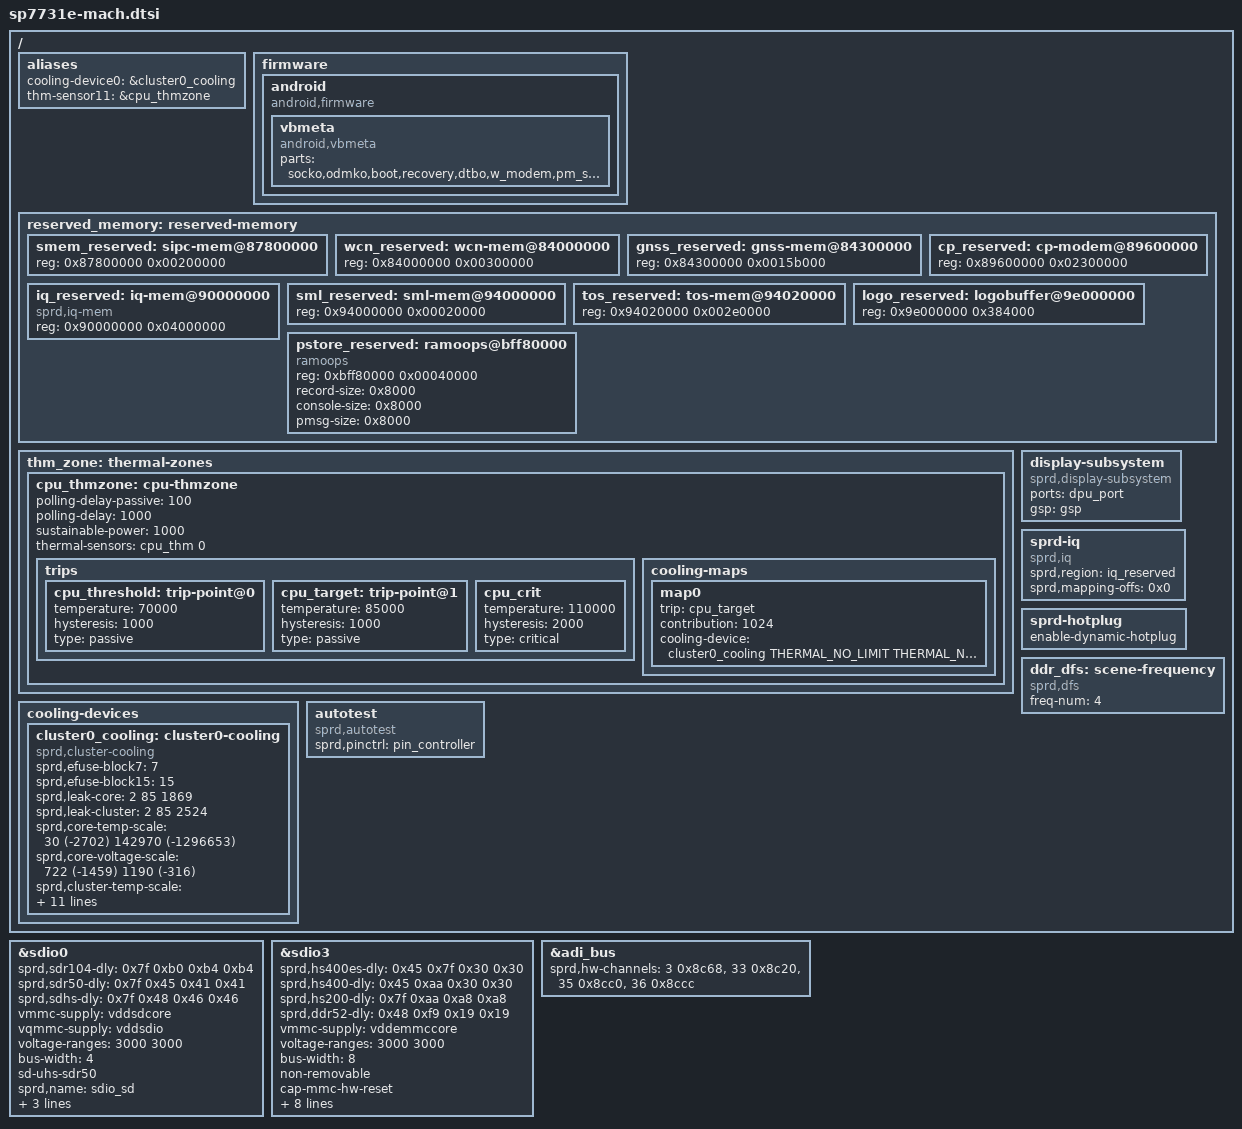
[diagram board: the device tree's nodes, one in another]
/*
 * Unisoc SP7731e board common DTS file
 *
 * Copyright (C) 2019, Unisoc Communications Inc.
 *
 * This file is licensed under a dual GPLv2 or X11 license.
 */
#include <dt-bindings/thermal/thermal.h>
/ {
	aliases {
		cooling-device0 = &cluster0_cooling;
		thm-sensor11 = &cpu_thmzone;
	};

	firmware {
		android {
			compatible = "android,firmware";
			vbmeta {
				compatible = "android,vbmeta";
				parts = "socko,odmko,boot,recovery,dtbo,w_modem,pm_sys,w_gdsp";
			};
		};
	};

	reserved_memory: reserved-memory {
		#address-cells = <1>;
		#size-cells = <1>;
		ranges;

		smem_reserved: sipc-mem@87800000 {
			reg = <0x87800000 0x00200000>;
		};

		/*start address must be 32M aligned */
		wcn_reserved: wcn-mem@84000000 {
			reg = <0x84000000 0x00300000>;
		};

		gnss_reserved: gnss-mem@84300000 {
			reg = <0x84300000 0x0015b000>;
		};

		cp_reserved: cp-modem@89600000 {
			reg = <0x89600000 0x02300000>;
		};

		/* only used for iq, will be removed in normal mode by uboot */
		iq_reserved: iq-mem@90000000 {
			compatible = "sprd,iq-mem";
			reg = <0x90000000 0x04000000>;
		};

		/*start address must be 64M aligned */
		sml_reserved: sml-mem@94000000 {
			reg = <0x94000000 0x00020000>;
		};

		tos_reserved: tos-mem@94020000 {
			reg = <0x94020000 0x002e0000>;
		};

		logo_reserved: logobuffer@9e000000 {
			reg = <0x9e000000 0x384000>;
		};

		pstore_reserved: ramoops@bff80000 {
			compatible = "ramoops";
			reg = <0xbff80000 0x00040000>;
			record-size = <0x8000>;
			console-size = <0x8000>;
			pmsg-size = <0x8000>;
		};

	};

	thm_zone: thermal-zones {
		cpu_thmzone: cpu-thmzone {
			polling-delay-passive = <100>;
			polling-delay = <1000>;
			sustainable-power = <1000>;
			thermal-sensors = <&cpu_thm 0>;
			trips {
				cpu_threshold: trip-point@0 {
					temperature = <70000>;
					hysteresis = <1000>;
					type = "passive";
				};
				cpu_target: trip-point@1 {
					temperature = <85000>;
					hysteresis = <1000>;
					type = "passive";
				};
				cpu_crit: cpu_crit {
					temperature = <110000>;
					hysteresis = <2000>;
					type = "critical";
				};
			};
			cooling-maps {
				map0 {
					trip = <&cpu_target>;
					contribution = <1024>;
					cooling-device =
					<&cluster0_cooling
						THERMAL_NO_LIMIT
						THERMAL_NO_LIMIT>;
				};
			};
		};
	};

	cooling-devices {
		cluster0_cooling: cluster0-cooling {
			compatible = "sprd,cluster-cooling";
			#cooling-cells = <2>; /* min followed by max */
			sprd,efuse-block7 = <7>;
			sprd,efuse-block15 = <15>;
			/* core_leak =                             */
			/*(LIT_LEAK[4:0]+1) x 2mA x 0.85V x 18.69% */
			sprd,leak-core = <2 85 1869>;
			/* cluster_leak =                           */
			/* (LIT_LEAK[4:0]+1) x 2mA x 0.85V x 25.24% */
			sprd,leak-cluster = <2 85 2524>;
			/*core Tscale = aT^3 + bT^2 + cT +di   */
			sprd,core-temp-scale =
			/* a*10^7   b*10^7      c*10^7     d*10^7 */
			<  30       (-2702)     142970     (-1296653)>;
			/*core Vscale = eV^3 + fV^2 + gV + h */
			sprd,core-voltage-scale =
			/* e*10^2   f*10^2     g*10^2  h*10^2*/
			<  722       (-1459)          1190      (-316)>;
			/*cluster Tscale = aT^3 + bT^2 + cT +di   */
			sprd,cluster-temp-scale =
			/* a*10^7   b*10^7      c*10^7     d*10^7 */
			<  30       (-2609)     139842     (-1206078)>;
			/*cluster Vscale = eV^3 + fV^2 + gV + h */
			sprd,cluster-voltage-scale =
			/* e*10^2   f*10^2     g*10^2  h*10^2*/
			<  614      (-1110)    821     (-188)>;
			sprd,efuse-switch = <0>;
			sprd,hotplug-period = <0>;
			sprd,min-cpufreq = <768000>;
			sprd,min-cpunum = <4>;
			sprd,core-base = <1139>;
			sprd,cluster-base = <2751>;
			sprd,dynamic-core =
			/*Pdynperghz    Freq     Vbase  */
			< 816           768      900>;
			sprd,dynamic-cluster =
			/*Pdynperghz    Freq     Vbase  */
			< 15           768      900>;
		};
	};

	display-subsystem {
		compatible = "sprd,display-subsystem";
		ports = <&dpu_port>;
		gsp = <&gsp>;
	};

	sprd-iq {
		compatible = "sprd,iq";
		sprd,region = <&iq_reserved>;
		sprd,mapping-offs = <0x0>;
	};

	sprd-hotplug {
		enable-dynamic-hotplug;
	};

	ddr_dfs: scene-frequency {
		compatible = "sprd,dfs";
		freq-num = <4>;
	};

	autotest:autotest{
		compatible = "sprd,autotest";
		sprd,pinctrl = <&pin_controller>;
	};
};

&sdio0 {
	sprd,sdr104-dly = <0x7f 0xb0 0xb4 0xb4>;
	sprd,sdr50-dly = <0x7f 0x45 0x41 0x41>;
	sprd,sdhs-dly = <0x7f 0x48 0x46 0x46>;
	vmmc-supply = <&vddsdcore>;
	vqmmc-supply = <&vddsdio>;
	voltage-ranges = <3000 3000>;
	bus-width = <4>;
	sd-uhs-sdr50;
	sprd,name = "sdio_sd";
	sprd,sdio-adma;
	no-sdio;
	no-mmc;
	status = "okay";
};

&sdio3 {
	sprd,hs400es-dly = <0x45 0x7f 0x30 0x30>;
	sprd,hs400-dly = <0x45 0xaa 0x30 0x30>;
	sprd,hs200-dly = <0x7f 0xaa 0xa8 0xa8>;
	sprd,ddr52-dly = <0x48 0xf9 0x19 0x19>;
	vmmc-supply = <&vddemmccore>;
	voltage-ranges = <3000 3000>;
	bus-width = <8>;
	non-removable;
	cap-mmc-hw-reset;
	mmc-hs400-enhanced-strobe;
	mmc-hs400-1_8v;
	mmc-hs200-1_8v;
	mmc-ddr-1_8v;
	sprd,name = "sdio_emmc";
	sprd,sdio-adma;
	no-sdio;
	no-sd;
	status = "okay";
};

&adi_bus {
	sprd,hw-channels = <3 0x8c68>, <33 0x8c20>,
		<35 0x8cc0>, <36 0x8ccc>;
};
